# nvic register map
Vendor: Texas Instruments
Peripheral module from a debugger description file (folder sc4cc231e6pm).
Registers are 32-bit, read-write, no defined reset value unless marked. A register's access mark holds for its fields unless they carry their own. Offsets are as the file gives them; lines under a group give offsets from that group; [hi:lo] are bit positions; {n}, {i} and the like mark numbered series; 'fields as' and 'values as' point back to an identical list; <NAME> marks a mode.

## NVIC — NVIC register addresses
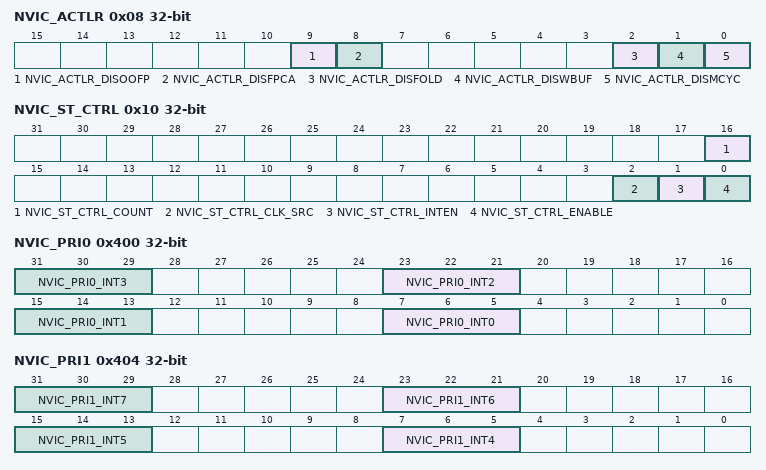
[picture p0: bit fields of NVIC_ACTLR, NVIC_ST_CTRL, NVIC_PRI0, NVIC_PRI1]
0x08 NVIC_ACTLR — Auxiliary Control
  [9] NVIC_ACTLR_DISOOFP — Disable Out-Of-Order Floating Point
  [8] NVIC_ACTLR_DISFPCA — Disable CONTROL
  [2] NVIC_ACTLR_DISFOLD — Disable IT Folding
  [1] NVIC_ACTLR_DISWBUF — Disable Write Buffer
  [0] NVIC_ACTLR_DISMCYC — Disable Interrupts of Multiple Cycle Instructions
0x10 NVIC_ST_CTRL — SysTick Control and Status Register
  [16] NVIC_ST_CTRL_COUNT — Count Flag
  [2] NVIC_ST_CTRL_CLK_SRC — Clock Source
  [1] NVIC_ST_CTRL_INTEN — Interrupt Enable
  [0] NVIC_ST_CTRL_ENABLE — Enable
0x14 NVIC_ST_RELOAD — SysTick Reload Value Register
  [23:0] NVIC_ST_RELOAD — Reload Value
0x18 NVIC_ST_CURRENT — SysTick Current Value Register
  [23:0] NVIC_ST_CURRENT — Current Value
{0x100+4i} NVIC_EN{i} (i=0..3) — Interrupt {32i}-{32i+31} Set Enable
  [31:0] NVIC_EN{i}_INT — Interrupt Enable
0x110 NVIC_EN4 — Interrupt 128-159 Set Enable
  [10:0] NVIC_EN4_INT — Interrupt Enable
{0x180+4i} NVIC_DIS{i} (i=0..3) — Interrupt {32i}-{32i+31} Clear Enable
  [31:0] NVIC_DIS{i}_INT — Interrupt Disable
0x190 NVIC_DIS4 — Interrupt 128-159 Clear Enable
  [10:0] NVIC_DIS4_INT — Interrupt Disable
{0x200+4i} NVIC_PEND{i} (i=0..3) — Interrupt {32i}-{32i+31} Set Pending
  [31:0] NVIC_PEND{i}_INT — Interrupt Set Pending
0x210 NVIC_PEND4 — Interrupt 128-159 Set Pending
  [10:0] NVIC_PEND4_INT — Interrupt Set Pending
{0x280+4i} NVIC_UNPEND{i} (i=0..3) — Interrupt {32i}-{32i+31} Clear Pending
  [31:0] NVIC_UNPEND{i}_INT — Interrupt Clear Pending
0x290 NVIC_UNPEND4 — Interrupt 128-159 Clear Pending
  [10:0] NVIC_UNPEND4_INT — Interrupt Clear Pending
{0x300+4i} NVIC_ACTIVE{i} ro (i=0..3) — Interrupt {32i}-{32i+31} Active Bit
  [31:0] NVIC_ACTIVE{i}_INT — Interrupt Active
0x310 NVIC_ACTIVE4 ro — Interrupt 128-159 Active Bit
  [10:0] NVIC_ACTIVE4_INT — Interrupt Active
0x400 NVIC_PRI0 — Interrupt 0-3 Priority
  [8n+7:8n+5] NVIC_PRI0_INT{n} (n=0..3) — Interrupt {n} Priority Mask
0x404 NVIC_PRI1 — Interrupt 4-7 Priority
  [8n-25:8n-27] NVIC_PRI1_INT{n} (n=4..7) — Interrupt {n} Priority Mask
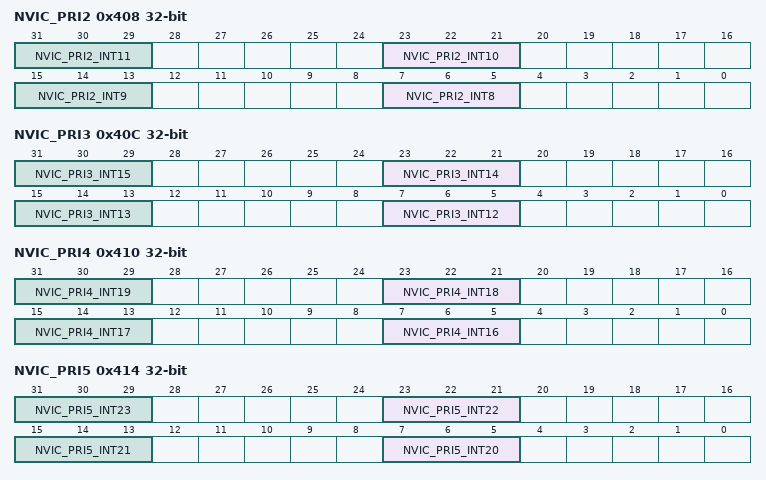
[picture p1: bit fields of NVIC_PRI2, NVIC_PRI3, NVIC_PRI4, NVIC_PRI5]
0x408 NVIC_PRI2 — Interrupt 8-11 Priority
  [8n-57:8n-59] NVIC_PRI2_INT{n} (n=8..11) — Interrupt {n} Priority Mask
0x40C NVIC_PRI3 — Interrupt 12-15 Priority
  [8n-89:8n-91] NVIC_PRI3_INT{n} (n=12..15) — Interrupt {n} Priority Mask
0x410 NVIC_PRI4 — Interrupt 16-19 Priority
  [8n-121:8n-123] NVIC_PRI4_INT{n} (n=16..19) — Interrupt {n} Priority Mask
0x414 NVIC_PRI5 — Interrupt 20-23 Priority
  [8n-153:8n-155] NVIC_PRI5_INT{n} (n=20..23) — Interrupt {n} Priority Mask
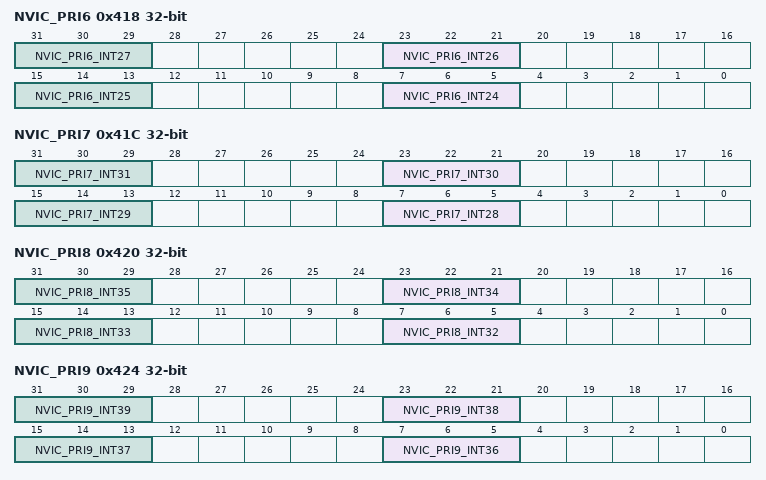
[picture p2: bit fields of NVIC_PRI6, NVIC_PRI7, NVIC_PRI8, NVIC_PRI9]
0x418 NVIC_PRI6 — Interrupt 24-27 Priority
  [8n-185:8n-187] NVIC_PRI6_INT{n} (n=24..27) — Interrupt {n} Priority Mask
0x41C NVIC_PRI7 — Interrupt 28-31 Priority
  [8n-217:8n-219] NVIC_PRI7_INT{n} (n=28..31) — Interrupt {n} Priority Mask
0x420 NVIC_PRI8 — Interrupt 32-35 Priority
  [8n-249:8n-251] NVIC_PRI8_INT{n} (n=32..35) — Interrupt {n} Priority Mask
0x424 NVIC_PRI9 — Interrupt 36-39 Priority
  [8n-281:8n-283] NVIC_PRI9_INT{n} (n=36..39) — Interrupt {n} Priority Mask
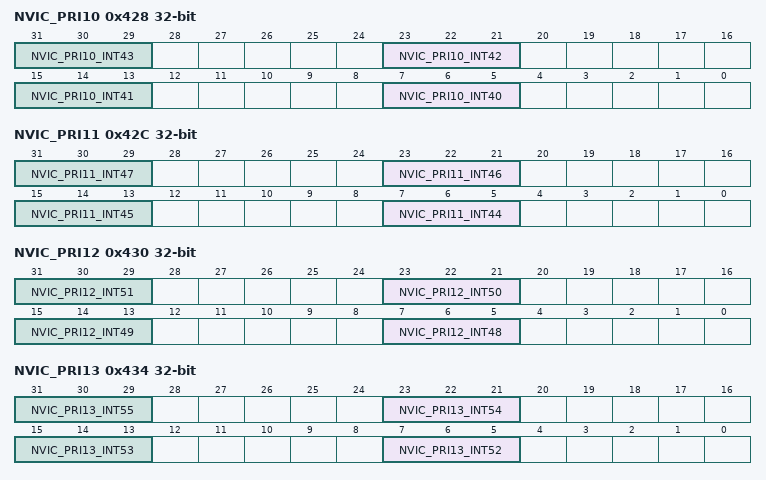
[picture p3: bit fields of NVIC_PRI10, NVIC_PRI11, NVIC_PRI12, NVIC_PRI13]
0x428 NVIC_PRI10 — Interrupt 40-43 Priority
  [8n-313:8n-315] NVIC_PRI10_INT{n} (n=40..43) — Interrupt {n} Priority Mask
0x42C NVIC_PRI11 — Interrupt 44-47 Priority
  [8n-345:8n-347] NVIC_PRI11_INT{n} (n=44..47) — Interrupt {n} Priority Mask
0x430 NVIC_PRI12 — Interrupt 48-51 Priority
  [8n-377:8n-379] NVIC_PRI12_INT{n} (n=48..51) — Interrupt {n} Priority Mask
0x434 NVIC_PRI13 — Interrupt 52-55 Priority
  [8n-409:8n-411] NVIC_PRI13_INT{n} (n=52..55) — Interrupt {n} Priority Mask
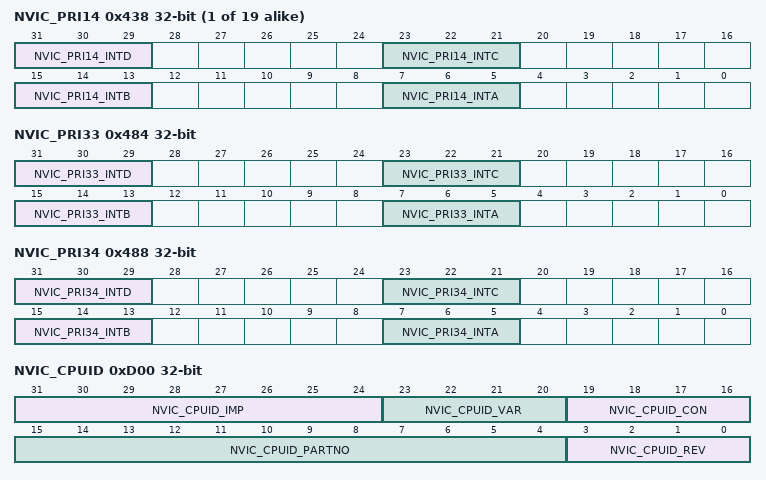
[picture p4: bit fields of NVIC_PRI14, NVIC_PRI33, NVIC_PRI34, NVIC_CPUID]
{0x400+4i} NVIC_PRI{i} (i=14..32) — Interrupt {4i}-{4i+3} Priority
  [31:29] NVIC_PRI{i}_INTD — Interrupt {4i+3} Priority Mask
  [23:21] NVIC_PRI{i}_INTC — Interrupt {4i+2} Priority Mask
  [15:13] NVIC_PRI{i}_INTB — Interrupt {4i+1} Priority Mask
  [7:5] NVIC_PRI{i}_INTA — Interrupt {4i} Priority Mask
0x484 NVIC_PRI33 — Interrupt 132-135 Priority
  [31:29] NVIC_PRI33_INTD — Interrupt Priority for Interrupt [4n+3]
  [23:21] NVIC_PRI33_INTC — Interrupt Priority for Interrupt [4n+2]
  [15:13] NVIC_PRI33_INTB — Interrupt Priority for Interrupt [4n+1]
  [7:5] NVIC_PRI33_INTA — Interrupt Priority for Interrupt [4n]
0x488 NVIC_PRI34 — Interrupt 136-139 Priority
  [31:29] NVIC_PRI34_INTD — Interrupt Priority for Interrupt [4n+3]
  [23:21] NVIC_PRI34_INTC — Interrupt Priority for Interrupt [4n+2]
  [15:13] NVIC_PRI34_INTB — Interrupt Priority for Interrupt [4n+1]
  [7:5] NVIC_PRI34_INTA — Interrupt Priority for Interrupt [4n]
0xD00 NVIC_CPUID ro — CPU ID Base
  [31:24] NVIC_CPUID_IMP — Implementer Code
    65=NVIC_CPUID_IMP_ARM (ARM)
  [23:20] NVIC_CPUID_VAR — Variant Number
  [19:16] NVIC_CPUID_CON — Constant
  [15:4] NVIC_CPUID_PARTNO — Part Number
    0xC24=NVIC_CPUID_PARTNO_CM4 (Cortex-M4 processor)
  [3:0] NVIC_CPUID_REV — Revision Number
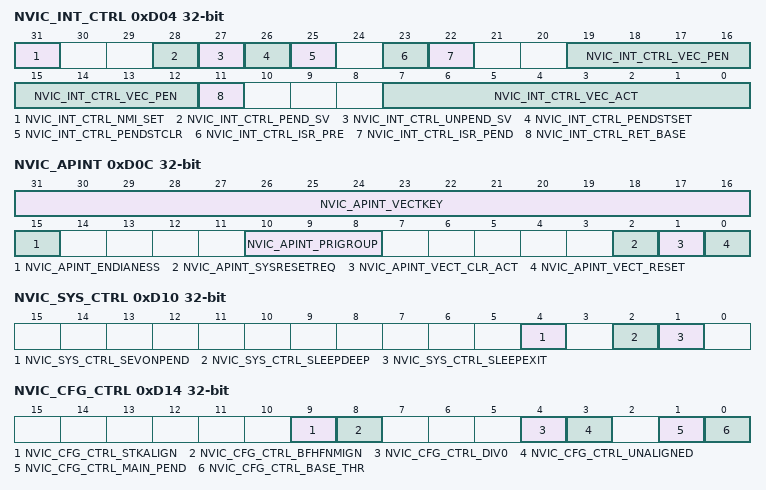
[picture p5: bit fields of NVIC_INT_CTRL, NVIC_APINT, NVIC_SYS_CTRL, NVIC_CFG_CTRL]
0xD04 NVIC_INT_CTRL — Interrupt Control and State
  [31] NVIC_INT_CTRL_NMI_SET — NMI Set Pending
  [28] NVIC_INT_CTRL_PEND_SV — PendSV Set Pending
  [27] NVIC_INT_CTRL_UNPEND_SV — PendSV Clear Pending
  [26] NVIC_INT_CTRL_PENDSTSET — SysTick Set Pending
  [25] NVIC_INT_CTRL_PENDSTCLR — SysTick Clear Pending
  [23] NVIC_INT_CTRL_ISR_PRE — Debug Interrupt Handling
  [22] NVIC_INT_CTRL_ISR_PEND — Interrupt Pending
  [19:12] NVIC_INT_CTRL_VEC_PEN — Interrupt Pending Vector Number
    2=NVIC_INT_CTRL_VEC_PEN_NMI (NMI); 3=NVIC_INT_CTRL_VEC_PEN_HARD (Hard fault); 4=NVIC_INT_CTRL_VEC_PEN_MEM (Memory management fault); 5=NVIC_INT_CTRL_VEC_PEN_BUS (Bus fault); 6=NVIC_INT_CTRL_VEC_PEN_USG (Usage fault); 11=NVIC_INT_CTRL_VEC_PEN_SVC (SVCall); 14=NVIC_INT_CTRL_VEC_PEN_PNDSV (PendSV); 15=NVIC_INT_CTRL_VEC_PEN_TICK (SysTick)
  [11] NVIC_INT_CTRL_RET_BASE — Return to Base
  [7:0] NVIC_INT_CTRL_VEC_ACT — Interrupt Pending Vector Number
0xD08 NVIC_VTABLE — Vector Table Offset
  [31:10] NVIC_VTABLE_OFFSET
0xD0C NVIC_APINT — Application Interrupt and Reset Control
  [31:16] NVIC_APINT_VECTKEY — Register Key
    0x5FA=NVIC_APINT_VECTKEY (Vector key)
  [15] NVIC_APINT_ENDIANESS — Data Endianess
  [10:8] NVIC_APINT_PRIGROUP — Interrupt Priority Grouping
    0=NVIC_APINT_PRIGROUP_7_1 (Priority group 7.1 split); 1=NVIC_APINT_PRIGROUP_6_2 (Priority group 6.2 split); 2=NVIC_APINT_PRIGROUP_5_3 (Priority group 5.3 split); 3=NVIC_APINT_PRIGROUP_4_4 (Priority group 4.4 split); 4=NVIC_APINT_PRIGROUP_3_5 (Priority group 3.5 split); 5=NVIC_APINT_PRIGROUP_2_6 (Priority group 2.6 split); 6=NVIC_APINT_PRIGROUP_1_7 (Priority group 1.7 split); 7=NVIC_APINT_PRIGROUP_0_8 (Priority group 0.8 split)
  [2] NVIC_APINT_SYSRESETREQ — System Reset Request
  [1] NVIC_APINT_VECT_CLR_ACT — Clear Active NMI / Fault
  [0] NVIC_APINT_VECT_RESET — System Reset
0xD10 NVIC_SYS_CTRL — System Control
  [4] NVIC_SYS_CTRL_SEVONPEND — Wake Up on Pending
  [2] NVIC_SYS_CTRL_SLEEPDEEP — Deep Sleep Enable
  [1] NVIC_SYS_CTRL_SLEEPEXIT — Sleep on ISR Exit
0xD14 NVIC_CFG_CTRL — Configuration and Control
  [9] NVIC_CFG_CTRL_STKALIGN — Stack Alignment on Exception Entry
  [8] NVIC_CFG_CTRL_BFHFNMIGN — Ignore Bus Fault in NMI and Fault
  [4] NVIC_CFG_CTRL_DIV0 — Trap on Divide by 0
  [3] NVIC_CFG_CTRL_UNALIGNED — Trap on Unaligned Access
  [1] NVIC_CFG_CTRL_MAIN_PEND — Allow Main Interrupt Trigger
  [0] NVIC_CFG_CTRL_BASE_THR — Thread State Control
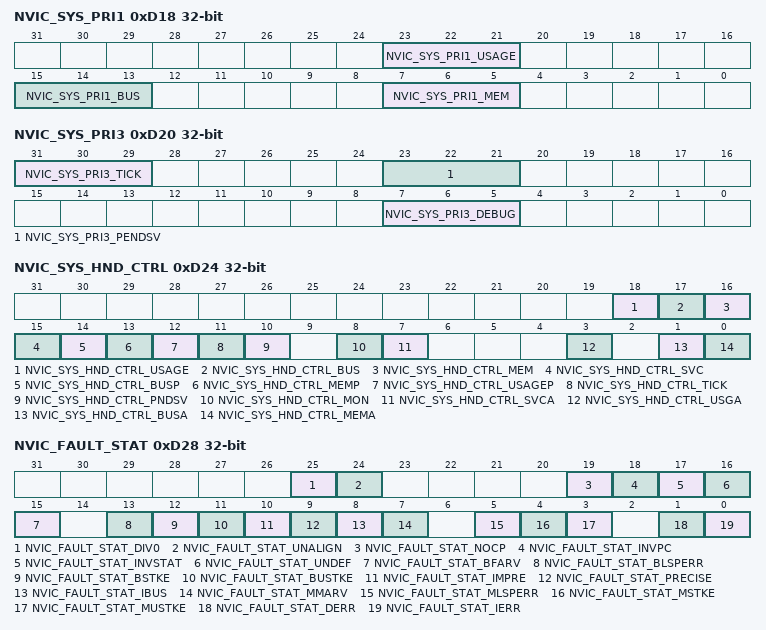
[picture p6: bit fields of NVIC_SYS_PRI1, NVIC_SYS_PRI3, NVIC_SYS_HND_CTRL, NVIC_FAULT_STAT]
0xD18 NVIC_SYS_PRI1 — System Handler Priority 1
  [23:21] NVIC_SYS_PRI1_USAGE — Usage Fault Priority
  [15:13] NVIC_SYS_PRI1_BUS — Bus Fault Priority
  [7:5] NVIC_SYS_PRI1_MEM — Memory Management Fault Priority
0xD1C NVIC_SYS_PRI2 — System Handler Priority 2
  [31:29] NVIC_SYS_PRI2_SVC — SVCall Priority
0xD20 NVIC_SYS_PRI3 — System Handler Priority 3
  [31:29] NVIC_SYS_PRI3_TICK — SysTick Exception Priority
  [23:21] NVIC_SYS_PRI3_PENDSV — PendSV Priority
  [7:5] NVIC_SYS_PRI3_DEBUG — Debug Priority
0xD24 NVIC_SYS_HND_CTRL — System Handler Control and State
  [18] NVIC_SYS_HND_CTRL_USAGE — Usage Fault Enable
  [17] NVIC_SYS_HND_CTRL_BUS — Bus Fault Enable
  [16] NVIC_SYS_HND_CTRL_MEM — Memory Management Fault Enable
  [15] NVIC_SYS_HND_CTRL_SVC — SVC Call Pending
  [14] NVIC_SYS_HND_CTRL_BUSP — Bus Fault Pending
  [13] NVIC_SYS_HND_CTRL_MEMP — Memory Management Fault Pending
  [12] NVIC_SYS_HND_CTRL_USAGEP — Usage Fault Pending
  [11] NVIC_SYS_HND_CTRL_TICK — SysTick Exception Active
  [10] NVIC_SYS_HND_CTRL_PNDSV — PendSV Exception Active
  [8] NVIC_SYS_HND_CTRL_MON — Debug Monitor Active
  [7] NVIC_SYS_HND_CTRL_SVCA — SVC Call Active
  [3] NVIC_SYS_HND_CTRL_USGA — Usage Fault Active
  [1] NVIC_SYS_HND_CTRL_BUSA — Bus Fault Active
  [0] NVIC_SYS_HND_CTRL_MEMA — Memory Management Fault Active
0xD28 NVIC_FAULT_STAT — Configurable Fault Status
  [25] NVIC_FAULT_STAT_DIV0 — Divide-by-Zero Usage Fault
  [24] NVIC_FAULT_STAT_UNALIGN — Unaligned Access Usage Fault
  [19] NVIC_FAULT_STAT_NOCP — No Coprocessor Usage Fault
  [18] NVIC_FAULT_STAT_INVPC — Invalid PC Load Usage Fault
  [17] NVIC_FAULT_STAT_INVSTAT — Invalid State Usage Fault
  [16] NVIC_FAULT_STAT_UNDEF — Undefined Instruction Usage Fault
  [15] NVIC_FAULT_STAT_BFARV — Bus Fault Address Register Valid
  [13] NVIC_FAULT_STAT_BLSPERR — Bus Fault on Floating-Point Lazy State Preservation
  [12] NVIC_FAULT_STAT_BSTKE — Stack Bus Fault
  [11] NVIC_FAULT_STAT_BUSTKE — Unstack Bus Fault
  [10] NVIC_FAULT_STAT_IMPRE — Imprecise Data Bus Error
  [9] NVIC_FAULT_STAT_PRECISE — Precise Data Bus Error
  [8] NVIC_FAULT_STAT_IBUS — Instruction Bus Error
  [7] NVIC_FAULT_STAT_MMARV — Memory Management Fault Address Register Valid
  [5] NVIC_FAULT_STAT_MLSPERR — Memory Management Fault on Floating-Point Lazy State Preservation
  [4] NVIC_FAULT_STAT_MSTKE — Stack Access Violation
  [3] NVIC_FAULT_STAT_MUSTKE — Unstack Access Violation
  [1] NVIC_FAULT_STAT_DERR — Data Access Violation
  [0] NVIC_FAULT_STAT_IERR — Instruction Access Violation
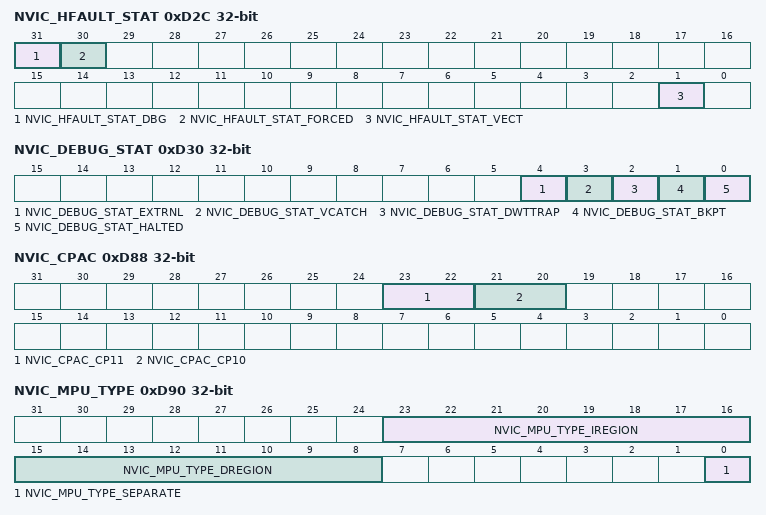
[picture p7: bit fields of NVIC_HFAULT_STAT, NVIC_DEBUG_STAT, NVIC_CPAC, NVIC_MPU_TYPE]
0xD2C NVIC_HFAULT_STAT — Hard Fault Status
  [31] NVIC_HFAULT_STAT_DBG — Debug Event
  [30] NVIC_HFAULT_STAT_FORCED — Forced Hard Fault
  [1] NVIC_HFAULT_STAT_VECT — Vector Table Read Fault
0xD30 NVIC_DEBUG_STAT — Debug Status Register
  [4] NVIC_DEBUG_STAT_EXTRNL — EDBGRQ asserted
  [3] NVIC_DEBUG_STAT_VCATCH — Vector catch
  [2] NVIC_DEBUG_STAT_DWTTRAP — DWT match
  [1] NVIC_DEBUG_STAT_BKPT — Breakpoint instruction
  [0] NVIC_DEBUG_STAT_HALTED — Halt request
0xD34 NVIC_MM_ADDR — Memory Management Fault Address
  [31:0] NVIC_MM_ADDR — Fault Address
0xD38 NVIC_FAULT_ADDR — Bus Fault Address
  [31:0] NVIC_FAULT_ADDR — Fault Address
0xD88 NVIC_CPAC — Coprocessor Access Control
  [23:22] NVIC_CPAC_CP11 — CP11 Coprocessor Access Privilege
    0=NVIC_CPAC_CP11_DIS (Access Denied); 1=NVIC_CPAC_CP11_PRIV (Privileged Access Only); 3=NVIC_CPAC_CP11_FULL (Full Access)
  [21:20] NVIC_CPAC_CP10 — CP10 Coprocessor Access Privilege
    0=NVIC_CPAC_CP10_DIS (Access Denied); 1=NVIC_CPAC_CP10_PRIV (Privileged Access Only); 3=NVIC_CPAC_CP10_FULL (Full Access)
0xD90 NVIC_MPU_TYPE ro — MPU Type
  [23:16] NVIC_MPU_TYPE_IREGION — Number of I Regions
  [15:8] NVIC_MPU_TYPE_DREGION — Number of D Regions
  [0] NVIC_MPU_TYPE_SEPARATE — Separate or Unified MPU
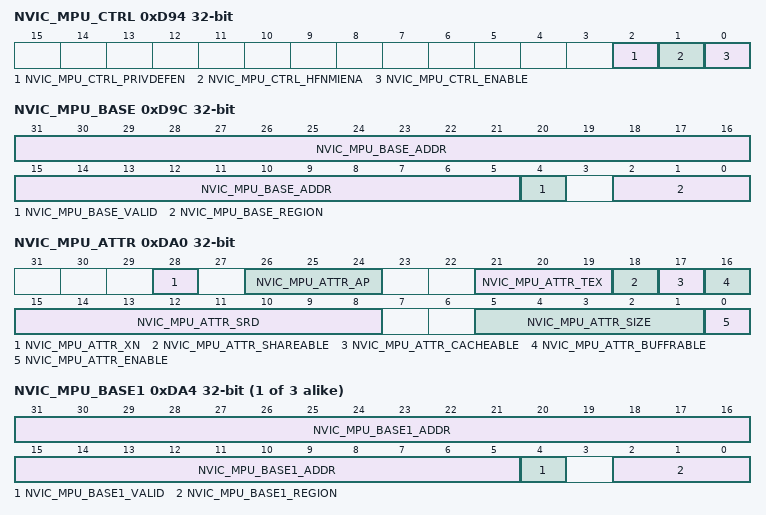
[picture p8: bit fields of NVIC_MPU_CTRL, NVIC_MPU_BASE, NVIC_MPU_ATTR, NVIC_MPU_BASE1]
0xD94 NVIC_MPU_CTRL — MPU Control
  [2] NVIC_MPU_CTRL_PRIVDEFEN — MPU Default Region
  [1] NVIC_MPU_CTRL_HFNMIENA — MPU Enabled During Faults
  [0] NVIC_MPU_CTRL_ENABLE — MPU Enable
0xD98 NVIC_MPU_NUMBER — MPU Region Number
  [2:0] NVIC_MPU_NUMBER — MPU Region to Access
0xD9C NVIC_MPU_BASE — MPU Region Base Address
  [31:5] NVIC_MPU_BASE_ADDR — Base Address Mask
  [4] NVIC_MPU_BASE_VALID — Region Number Valid
  [2:0] NVIC_MPU_BASE_REGION — Region Number
0xDA0 NVIC_MPU_ATTR — MPU Region Attribute and Size
  [28] NVIC_MPU_ATTR_XN — Instruction Access Disable
  [26:24] NVIC_MPU_ATTR_AP — Access Privilege
  [21:19] NVIC_MPU_ATTR_TEX — Type Extension Mask
  [18] NVIC_MPU_ATTR_SHAREABLE — Shareable
  [17] NVIC_MPU_ATTR_CACHEABLE — Cacheable
  [16] NVIC_MPU_ATTR_BUFFRABLE — Bufferable
  [15:8] NVIC_MPU_ATTR_SRD — Subregion Disable Bits
  [5:1] NVIC_MPU_ATTR_SIZE — Region Size Mask
  [0] NVIC_MPU_ATTR_ENABLE — Region Enable
{0xD9C+8i} NVIC_MPU_BASE{i} (i=1..3) — MPU Region Base Address Alias {i}
  [31:5] NVIC_MPU_BASE{i}_ADDR — Base Address Mask
  [4] NVIC_MPU_BASE{i}_VALID — Region Number Valid
  [2:0] NVIC_MPU_BASE{i}_REGION — Region Number
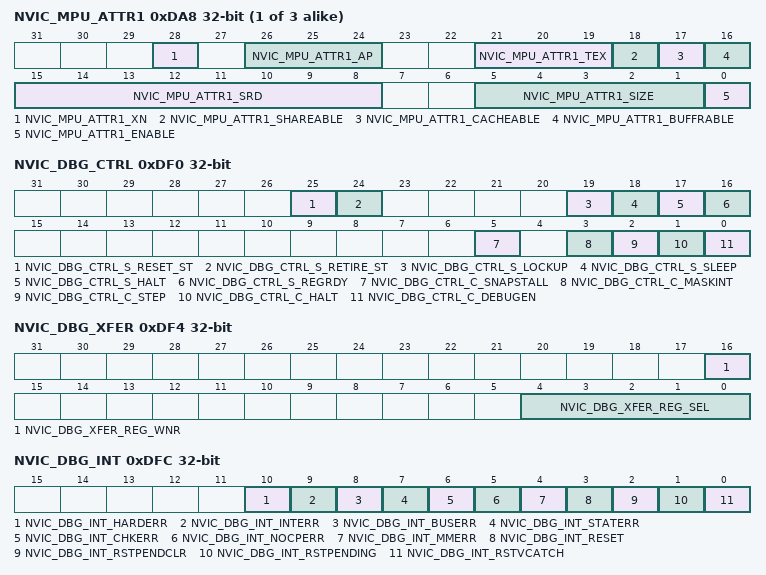
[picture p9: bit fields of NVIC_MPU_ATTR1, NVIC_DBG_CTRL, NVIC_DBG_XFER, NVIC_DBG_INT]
{0xDA0+8i} NVIC_MPU_ATTR{i} (i=1..3) — MPU Region Attribute and Size Alias {i}
  [28] NVIC_MPU_ATTR{i}_XN — Instruction Access Disable
  [26:24] NVIC_MPU_ATTR{i}_AP — Access Privilege
  [21:19] NVIC_MPU_ATTR{i}_TEX — Type Extension Mask
  [18] NVIC_MPU_ATTR{i}_SHAREABLE — Shareable
  [17] NVIC_MPU_ATTR{i}_CACHEABLE — Cacheable
  [16] NVIC_MPU_ATTR{i}_BUFFRABLE — Bufferable
  [15:8] NVIC_MPU_ATTR{i}_SRD — Subregion Disable Bits
  [5:1] NVIC_MPU_ATTR{i}_SIZE — Region Size Mask
  [0] NVIC_MPU_ATTR{i}_ENABLE — Region Enable
0xDF0 NVIC_DBG_CTRL — Debug Control and Status Reg
  [31:16] NVIC_DBG_CTRL_DBGKEY — Debug key mask
    0xA05F=NVIC_DBG_CTRL_DBGKEY (Debug key)
0xDF0 NVIC_DBG_CTRL ro — Debug Control and Status Reg
  [25] NVIC_DBG_CTRL_S_RESET_ST — Core has reset since last read
  [24] NVIC_DBG_CTRL_S_RETIRE_ST — Core has executed insruction since last read
  [19] NVIC_DBG_CTRL_S_LOCKUP — Core is locked up
  [18] NVIC_DBG_CTRL_S_SLEEP — Core is sleeping
  [17] NVIC_DBG_CTRL_S_HALT — Core status on halt
  [16] NVIC_DBG_CTRL_S_REGRDY — Register read/write available
  [5] NVIC_DBG_CTRL_C_SNAPSTALL — Breaks a stalled load/store
  [3] NVIC_DBG_CTRL_C_MASKINT — Mask interrupts when stepping
  [2] NVIC_DBG_CTRL_C_STEP — Step the core
  [1] NVIC_DBG_CTRL_C_HALT — Halt the core
  [0] NVIC_DBG_CTRL_C_DEBUGEN — Enable debug
0xDF4 NVIC_DBG_XFER — Debug Core Reg. Transfer Select
  [16] NVIC_DBG_XFER_REG_WNR — Write or not read
  [4:0] NVIC_DBG_XFER_REG_SEL — Register
    {v}=NVIC_DBG_XFER_REG_R{v} (Register R{v}) (v=0..15); 16=NVIC_DBG_XFER_REG_FLAGS (xPSR/Flags register); 17=NVIC_DBG_XFER_REG_MSP (Main SP); 18=NVIC_DBG_XFER_REG_PSP (Process SP); 19=NVIC_DBG_XFER_REG_DSP (Deep SP); 20=NVIC_DBG_XFER_REG_CFBP (Control/Fault/BasePri/PriMask)
0xDF8 NVIC_DBG_DATA — Debug Core Register Data
  [31:0] NVIC_DBG_DATA — Data temporary cache
0xDFC NVIC_DBG_INT — Debug Reset Interrupt Control
  [10] NVIC_DBG_INT_HARDERR — Debug trap on hard fault
  [9] NVIC_DBG_INT_INTERR — Debug trap on interrupt errors
  [8] NVIC_DBG_INT_BUSERR — Debug trap on bus error
  [7] NVIC_DBG_INT_STATERR — Debug trap on usage fault state
  [6] NVIC_DBG_INT_CHKERR — Debug trap on usage fault check
  [5] NVIC_DBG_INT_NOCPERR — Debug trap on coprocessor error
  [4] NVIC_DBG_INT_MMERR — Debug trap on mem manage fault
  [3] NVIC_DBG_INT_RESET — Core reset status
  [2] NVIC_DBG_INT_RSTPENDCLR — Clear pending core reset
  [1] NVIC_DBG_INT_RSTPENDING — Core reset is pending
  [0] NVIC_DBG_INT_RSTVCATCH — Reset vector catch
0xF00 NVIC_SW_TRIG wo — Software Trigger Interrupt
  [7:0] NVIC_SW_TRIG_INTID — Interrupt ID
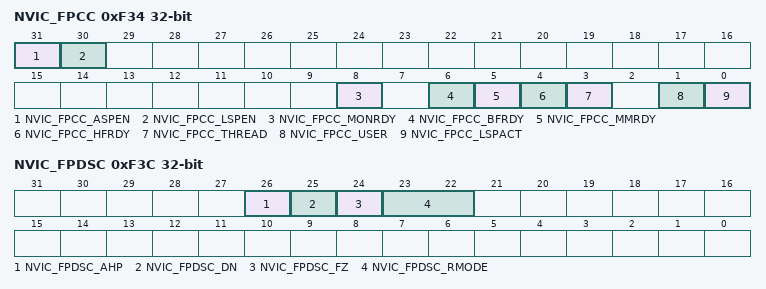
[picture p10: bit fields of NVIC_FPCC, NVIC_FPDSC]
0xF34 NVIC_FPCC — Floating-Point Context Control
  [31] NVIC_FPCC_ASPEN — Automatic State Preservation Enable
  [30] NVIC_FPCC_LSPEN — Lazy State Preservation Enable
  [8] NVIC_FPCC_MONRDY — Monitor Ready
  [6] NVIC_FPCC_BFRDY — Bus Fault Ready
  [5] NVIC_FPCC_MMRDY — Memory Management Fault Ready
  [4] NVIC_FPCC_HFRDY — Hard Fault Ready
  [3] NVIC_FPCC_THREAD — Thread Mode
  [1] NVIC_FPCC_USER — User Privilege Level
  [0] NVIC_FPCC_LSPACT — Lazy State Preservation Active
0xF38 NVIC_FPCA — Floating-Point Context Address
  [31:3] NVIC_FPCA_ADDRESS — Address
0xF3C NVIC_FPDSC — Floating-Point Default Status Control
  [26] NVIC_FPDSC_AHP — AHP Bit Default
  [25] NVIC_FPDSC_DN — DN Bit Default
  [24] NVIC_FPDSC_FZ — FZ Bit Default
  [23:22] NVIC_FPDSC_RMODE — RMODE Bit Default
    0=NVIC_FPDSC_RMODE_RN (Round to Nearest (RN) mode); 1=NVIC_FPDSC_RMODE_RP (Round towards Plus Infinity (RP) mode); 2=NVIC_FPDSC_RMODE_RM (Round towards Minus Infinity (RM) mode); 3=NVIC_FPDSC_RMODE_RZ (Round towards Zero (RZ) mode)
